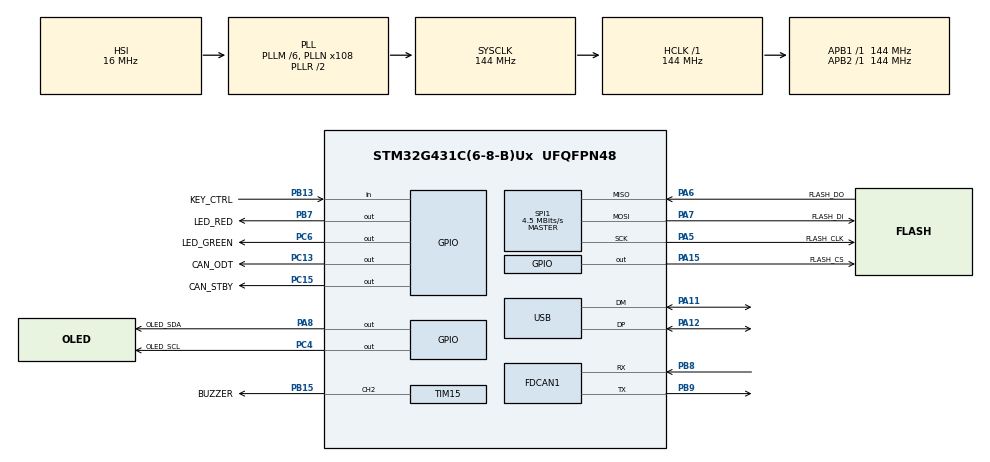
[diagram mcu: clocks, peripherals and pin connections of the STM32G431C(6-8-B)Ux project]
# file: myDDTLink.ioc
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FATFS._CODE_PAGE=936
FATFS._MAX_SS=4096
FDCAN1.CalculateBaudRateNominal=1000000
FDCAN1.CalculateTimeBitNominal=1000
FDCAN1.CalculateTimeQuantumNominal=111.11111111111111
FDCAN1.ClockDivider=FDCAN_CLOCK_DIV2
FDCAN1.NominalPrescaler=8
FDCAN1.NominalTimeSeg1=4
FDCAN1.NominalTimeSeg2=4
Mcu.Family=STM32G4
Mcu.Name=STM32G431C(6-8-B)Ux
Mcu.Package=UFQFPN48
NVIC.FDCAN1_IT0_IRQn=true\:0\:0\:false\:false\:true\:true\:true\:true
NVIC.PriorityGroup=NVIC_PRIORITYGROUP_4
NVIC.USB_LP_IRQn=true\:0\:0\:false\:false\:true\:false\:true\:true
PA11.Mode=Device
PA11.Signal=USB_DM
PA12.Mode=Device
PA12.Signal=USB_DP
PA13.Mode=Serial_Wire
PA13.Signal=SYS_JTMS-SWDIO
PA14.Mode=Serial_Wire
PA14.Signal=SYS_JTCK-SWCLK
PA15.GPIO_Label=FLASH_CS
PA15.GPIO_Speed=GPIO_SPEED_FREQ_VERY_HIGH
PA15.PinState=GPIO_PIN_SET
PA15.Signal=GPIO_Output
PA5.GPIO_Label=FLASH_CLK
PA5.GPIO_PuPd=GPIO_PULLUP
PA5.GPIO_Speed=GPIO_SPEED_FREQ_VERY_HIGH
PA5.Mode=Full_Duplex_Master
PA5.Signal=SPI1_SCK
PA6.GPIO_Label=FLASH_DO
PA6.GPIO_Speed=GPIO_SPEED_FREQ_VERY_HIGH
PA6.Mode=Full_Duplex_Master
PA6.Signal=SPI1_MISO
PA7.GPIO_Label=FLASH_DI
PA7.GPIO_Speed=GPIO_SPEED_FREQ_VERY_HIGH
PA7.Mode=Full_Duplex_Master
PA7.Signal=SPI1_MOSI
PA8.GPIO_Label=OLED_SDA
PA8.GPIO_ModeDefaultOutputPP=GPIO_MODE_OUTPUT_OD
PA8.GPIO_PuPd=GPIO_PULLUP
PA8.GPIO_Speed=GPIO_SPEED_FREQ_HIGH
PA8.Signal=GPIO_Output
PB13.GPIO_Label=KEY_CTRL
PB13.Signal=GPIO_Input
PB15.GPIO_Label=BUZZER
PB15.GPIO_Speed=GPIO_SPEED_FREQ_HIGH
PB15.Signal=S_TIM15_CH2
PB7.GPIO_Label=LED_RED
PB7.GPIO_Speed=GPIO_SPEED_FREQ_MEDIUM
PB7.PinState=GPIO_PIN_SET
PB7.Signal=GPIO_Output
PB8-BOOT0.GPIO_FM8=__NULL
PB8-BOOT0.GPIO_Mode=GPIO_MODE_AF_PP
PB8-BOOT0.GPIO_PuPd=GPIO_NOPULL
PB8-BOOT0.GPIO_Speed=GPIO_SPEED_FREQ_LOW
PB8-BOOT0.Mode=FDCAN_Activate
PB8-BOOT0.Signal=FDCAN1_RX
PB9.GPIO_FM9=__NULL
PB9.GPIO_Mode=GPIO_MODE_AF_PP
PB9.GPIO_PuPd=GPIO_NOPULL
PB9.GPIO_Speed=GPIO_SPEED_FREQ_LOW
PB9.Mode=FDCAN_Activate
PB9.Signal=FDCAN1_TX
PC13.GPIO_Label=CAN_ODT
PC13.GPIO_PuPd=GPIO_NOPULL
PC13.Signal=GPIO_Output
PC15-OSC32_OUT.GPIO_Label=CAN_STBY
PC15-OSC32_OUT.Signal=GPIO_Output
PC4.GPIO_Label=OLED_SCL
PC4.GPIO_ModeDefaultOutputPP=GPIO_MODE_OUTPUT_OD
PC4.GPIO_PuPd=GPIO_PULLUP
PC4.GPIO_Speed=GPIO_SPEED_FREQ_HIGH
PC4.Signal=GPIO_Output
PC6.GPIO_Label=LED_GREEN
PC6.GPIO_Speed=GPIO_SPEED_FREQ_HIGH
PC6.PinState=GPIO_PIN_SET
PC6.Signal=GPIO_Output
PF0-OSC_IN.Mode=HSE-External-Oscillator
PF0-OSC_IN.Signal=RCC_OSC_IN
PF1-OSC_OUT.Mode=HSE-External-Oscillator
PF1-OSC_OUT.Signal=RCC_OSC_OUT
ProjectManager.HeapSize=0x800
ProjectManager.StackSize=0x3000
ProjectManager.TargetToolchain=MDK-ARM V5.32
RCC.ADC12Freq_Value=144000000
RCC.AHBFreq_Value=144000000
RCC.APB1Freq_Value=144000000
RCC.APB1TimFreq_Value=144000000
RCC.APB2Freq_Value=144000000
RCC.APB2TimFreq_Value=144000000
RCC.CortexFreq_Value=144000000
RCC.EXTERNAL_CLOCK_VALUE=12288000
RCC.HCLKFreq_Value=144000000
RCC.HSE_VALUE=8000000
RCC.HSI48_VALUE=48000000
RCC.HSI_VALUE=16000000
RCC.LSE_VALUE=32768
RCC.PLLM=RCC_PLLM_DIV6
RCC.PLLN=108
RCC.PLLQ=RCC_PLLQ_DIV6
RCC.SYSCLKFreq_VALUE=144000000
RCC.SYSCLKSource=RCC_SYSCLKSOURCE_PLLCLK
RCC.USBFreq_Value=48000000
RCC.VCOOutputFreq_Value=288000000
SH.S_TIM15_CH2.0=TIM15_CH2,PWM Generation2 CH2
SPI1.BaudRatePrescaler=SPI_BAUDRATEPRESCALER_32
SPI1.CalculateBaudRate=4.5 MBits/s
SPI1.DataSize=SPI_DATASIZE_8BIT
SPI1.Direction=SPI_DIRECTION_2LINES
SPI1.Mode=SPI_MODE_MASTER
SPI1.VirtualType=VM_MASTER
TIM15.AutoReloadPreload=TIM_AUTORELOAD_PRELOAD_ENABLE
TIM15.Channel-PWM\ Generation2\ CH2=TIM_CHANNEL_2
TIM15.PeriodNoDither=499
TIM15.Prescaler=60
USB_DEVICE.APP_RX_DATA_SIZE=64
USB_DEVICE.APP_TX_DATA_SIZE=64
USB_DEVICE.CLASS_NAME_FS=CDC
USB_DEVICE.CONFIGURATION_STRING_CDC_FS=CDC Config
USB_DEVICE.INTERFACE_STRING_CDC_FS=CDC Interface
USB_DEVICE.MANUFACTURER_STRING=DirectDriveTech
USB_DEVICE.PID_CDC_FS=22333
USB_DEVICE.PRODUCT_STRING_CDC_FS=DDT Link
USB_DEVICE.USBD_LPM_ENABLED=0
USB_DEVICE.VirtualMode=Cdc
USB_DEVICE.VirtualModeFS=Cdc_FS
VP_FATFS_VS_Generic.Mode=User_defined
VP_SYS_VS_DBSignals.Mode=DisableDeadBatterySignals
VP_USB_DEVICE_VS_USB_DEVICE_CDC_FS.Mode=CDC_FS
board=custom

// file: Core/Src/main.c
/* USER CODE BEGIN Header */
/**
 ******************************************************************************
 * @file           : main.c
 * @brief          : Main program body
 ******************************************************************************
 * @attention
 *
 * Copyright (c) 2024 STMicroelectronics.
 * All rights reserved.
 *
 * This software is licensed under terms that can be found in the LICENSE file
 * in the root directory of this software component.
 * If no LICENSE file comes with this software, it is provided AS-IS.
 *
 ******************************************************************************
 */
/* USER CODE END Header */
#include "main.h"
#include "app_fatfs.h"
#include "fdcan.h"
#include "spi.h"
#include "tim.h"
#include "usb_device.h"
#include "gpio.h"

/* USER CODE BEGIN Includes */
#include "device.h"
#include "task_schedule.h"
#include "task_usb2can.h"

/* USER CODE END Includes */

void SystemClock_Config(void);

int main(void)
{

  /* MCU Configuration--------------------------------------------------------*/

  /* Reset of all peripherals, Initializes the Flash interface and the Systick. */
  HAL_Init();

  /* Configure the system clock */
  SystemClock_Config();

  /* Initialize all configured peripherals */
  MX_GPIO_Init();
  MX_TIM15_Init();
  MX_FDCAN1_Init();
  MX_USB_Device_Init();
  MX_SPI1_Init();
  if (MX_FATFS_Init() != APP_OK) {
    Error_Handler();
  }

  /* Infinite loop */
  /* USER CODE BEGIN WHILE */

    /* task register */
    schedule_register();
    device_register();

    while (1)
    {
        // start the task scheduler
        schedule_start();
        mytask_usb2can_entry();

    /* USER CODE END WHILE */

    }
}

void SystemClock_Config(void)
{
  RCC_OscInitTypeDef RCC_OscInitStruct = {0};
  RCC_ClkInitTypeDef RCC_ClkInitStruct = {0};

  /** Configure the main internal regulator output voltage
  */
  HAL_PWREx_ControlVoltageScaling(PWR_REGULATOR_VOLTAGE_SCALE1);

  /** Initializes the RCC Oscillators according to the specified parameters
  * in the RCC_OscInitTypeDef structure.
  */
  RCC_OscInitStruct.OscillatorType = RCC_OSCILLATORTYPE_HSI;
  RCC_OscInitStruct.HSIState = RCC_HSI_ON;
  RCC_OscInitStruct.HSICalibrationValue = RCC_HSICALIBRATION_DEFAULT;
  RCC_OscInitStruct.PLL.PLLState = RCC_PLL_ON;
  RCC_OscInitStruct.PLL.PLLSource = RCC_PLLSOURCE_HSI;
  RCC_OscInitStruct.PLL.PLLM = RCC_PLLM_DIV6;
  RCC_OscInitStruct.PLL.PLLN = 108;
  RCC_OscInitStruct.PLL.PLLP = RCC_PLLP_DIV2;
  RCC_OscInitStruct.PLL.PLLQ = RCC_PLLQ_DIV6;
  RCC_OscInitStruct.PLL.PLLR = RCC_PLLR_DIV2;
  if (HAL_RCC_OscConfig(&RCC_OscInitStruct) != HAL_OK)
  {
    Error_Handler();
  }

  /** Initializes the CPU, AHB and APB buses clocks
  */
  RCC_ClkInitStruct.ClockType = RCC_CLOCKTYPE_HCLK|RCC_CLOCKTYPE_SYSCLK
                              |RCC_CLOCKTYPE_PCLK1|RCC_CLOCKTYPE_PCLK2;
  RCC_ClkInitStruct.SYSCLKSource = RCC_SYSCLKSOURCE_PLLCLK;
  RCC_ClkInitStruct.AHBCLKDivider = RCC_SYSCLK_DIV1;
  RCC_ClkInitStruct.APB1CLKDivider = RCC_HCLK_DIV1;
  RCC_ClkInitStruct.APB2CLKDivider = RCC_HCLK_DIV1;

  if (HAL_RCC_ClockConfig(&RCC_ClkInitStruct, FLASH_LATENCY_4) != HAL_OK)
  {
    Error_Handler();
  }
}

void Error_Handler(void)
{
    __disable_irq();
    while (1)
    {
    }
}
